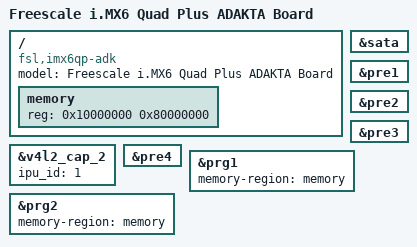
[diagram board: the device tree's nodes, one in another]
/* 
 * Copyright 2017 Adakta, Inc.
 * Copyright 2013 Boundary Devices
 * Copyright 2012 Freescale Semiconductor, Inc.
 * Copyright 2011 Linaro Ltd.
 *
 * The code contained herein is licensed under the GNU General Public
 * License. You may obtain a copy of the GNU General Public License
 * Version 2 or later at the following locations:
 *
 * http://www.opensource.org/licenses/gpl-license.html
 * http://www.gnu.org/copyleft/gpl.html
 */

/dts-v1/;

#include "imx6q.dtsi"
#include "imx6qp.dtsi"
#include "imx6qd-adakta_adk.dtsi"

/ {
	model = "Freescale i.MX6 Quad Plus ADAKTA Board";
	compatible = "fsl,imx6qp-adk", "fsl,imx6q";

	memory: memory {
		reg = <0x10000000 0x80000000>;
	};
};


&sata {
	status = "okay";
};

&v4l2_cap_2 {
	ipu_id = <1>;
};

&pre1 {
	status = "okay";
};

&pre2 {
	status = "okay";
};

&pre3 {
	status = "okay";
};

&pre4 {
	status = "okay";
};

&prg1 {
	memory-region = <&memory>;
	status = "okay";
};

&prg2 {
	memory-region = <&memory>;
	status = "okay";
};

